# pll register map
Vendor: Texas Instruments
Peripheral module from a debugger description file (folder Keystone).
Registers are 32-bit, read-write, no defined reset value unless marked. A register's access mark holds for its fields unless they carry their own. Offsets are as the file gives them; lines under a group give offsets from that group; [hi:lo] are bit positions; {n}, {i} and the like mark numbered series; 'fields as' and 'values as' point back to an identical list; <NAME> marks a mode.

## PLL
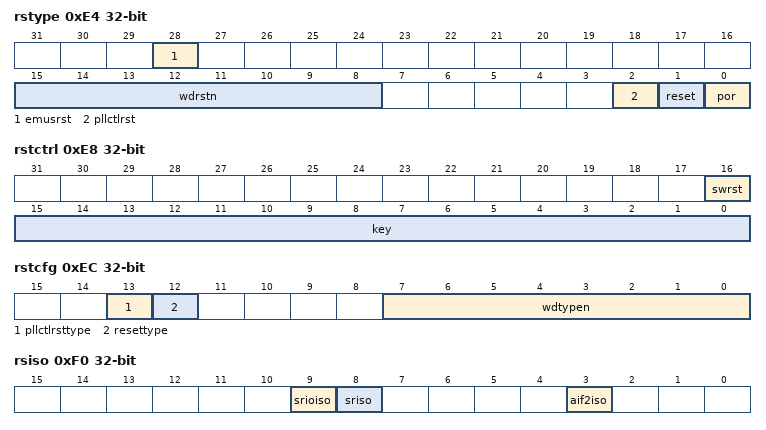
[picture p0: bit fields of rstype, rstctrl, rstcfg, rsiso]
0xE4 rstype
  [28] emusrst, [15:8] wdrstn, [2] pllctlrst, [1] reset, [0] por
0xE8 rstctrl
  [16] swrst, [15:0] key
0xEC rstcfg
  [13] pllctlrsttype, [12] resettype, [7:0] wdtypen
0xF0 rsiso
  [9] srioiso, [8] sriso, [3] aif2iso
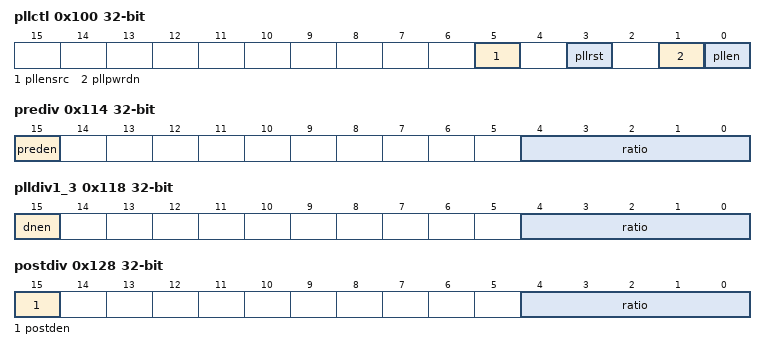
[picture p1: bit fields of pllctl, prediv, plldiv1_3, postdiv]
0x100 pllctl
  [5] pllensrc, [3] pllrst, [1] pllpwrdn, [0] pllen
0x108 secctl
  [23:16] pllsecctl
0x110 pllm
  [4:0] pllm
0x114 prediv
  [15] preden, [4:0] ratio
0x118 plldiv1_3 — (1 of 3, stride 4)
  [15] dnen, [4:0] ratio
0x128 postdiv
  [15] postden, [4:0] ratio
0x138 pllcmd
  [0] goset
0x13C pllstat
  [0] gostat
0x140 alnctl
  [15:0] aln1_16
0x144 dchange
  [15:0] sys1_16
0x148 cken
  [0] auxen
0x14C ckstat
  [0] auxon
0x150 systat
  [15:0] sys1_16on
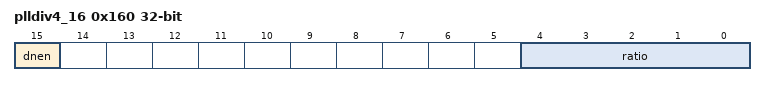
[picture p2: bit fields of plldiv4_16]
0x160 plldiv4_16 — (1 of 13, stride 4)
  [15] dnen, [4:0] ratio
